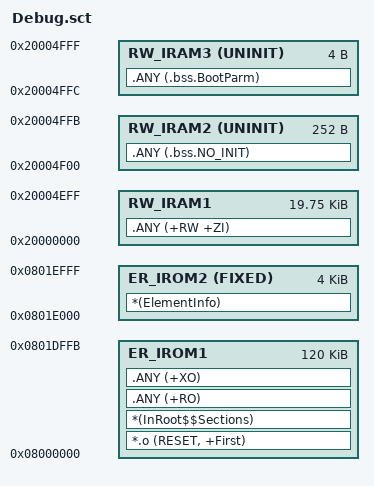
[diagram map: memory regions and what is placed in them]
; *************************************************************
; *** Scatter-Loading Description File generated by uVision ***
; *************************************************************

LR_IROM1 0x08000000 0x0001E000  {    ; load region size_region
  ER_IROM1 +0 0x0001DFFC  {  ; load address = execution address
   *.o (RESET, +First)
   *(InRoot$$Sections)
   .ANY (+RO)
   .ANY (+XO)
  }
  RW_IRAM1 0x20000000 0x00004F00  {  ; RW data
   .ANY (+RW +ZI)
  }
  RW_IRAM2 0x20004F00 UNINIT 0x000000FC  {
   .ANY (.bss.NO_INIT)
  }
  RW_IRAM3 0x20004FFC UNINIT 0x00000004  {
   .ANY (.bss.BootParm)
  }

}
LR_IROM2 0x0801E000 0x00001000  {    ; load region size_region
  ER_IROM2 +0 FIXED 0x00001000  {  ; load address = execution address
   *(ElementInfo)
  }
}


